# M368 register map
File version: 0.1
CPU: 
Registers are 32-bit, read-write, reset 0x0 unless marked. A register's access mark holds for its fields unless they carry their own. Offsets are from the block's base; [hi:lo] are bit positions; {n}, {i} and the like mark numbered series.

## PB — General Purpose Input_Output Port (PB)
Base 0x400C0100
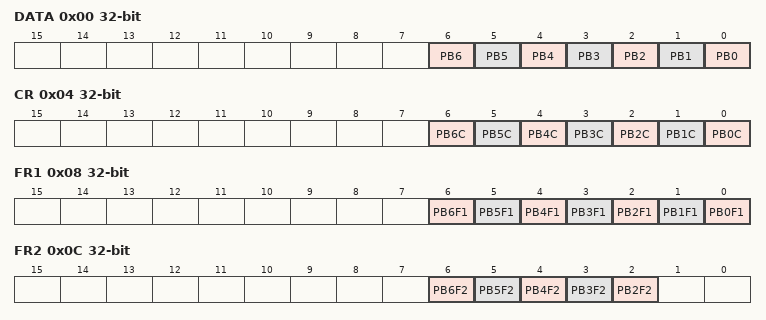
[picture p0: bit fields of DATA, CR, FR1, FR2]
0x00 DATA — PB Data Register
  [n] PB{n} (n=0..6)
0x04 CR — PB Control Register
  [n] PB{n}C (n=0..6)
0x08 FR1 — PB Function Register 1
  [n] PB{n}F1 (n=0..6)
0x0C FR2 — PB Function Register 2
  [n] PB{n}F2 (n=2..6)
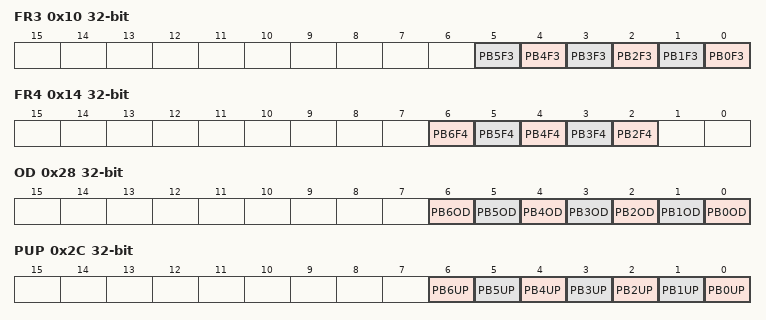
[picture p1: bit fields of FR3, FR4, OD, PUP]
0x10 FR3 — PB Function Register 3
  [n] PB{n}F3 (n=0..5)
0x14 FR4 — PB Function Register 4
  [n] PB{n}F4 (n=2..6)
0x28 OD — PB Open Drain Control Register
  [n] PB{n}OD (n=0..6)
0x2C PUP — PB Pull-Up Control Register
  [n] PB{n}UP (n=0..6)
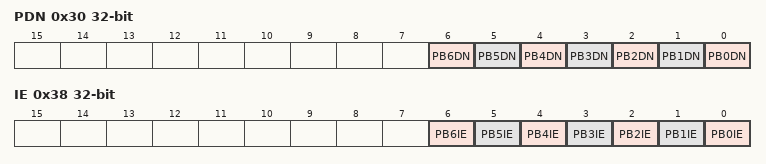
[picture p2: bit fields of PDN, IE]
0x30 PDN — PB Pull-Down Control Register
  [n] PB{n}DN (n=0..6)
0x38 IE — PB Input Enable Control Register
  [n] PB{n}IE (n=0..6)

## PE — General Purpose Input_Output Port (PE)
Base 0x400C0400
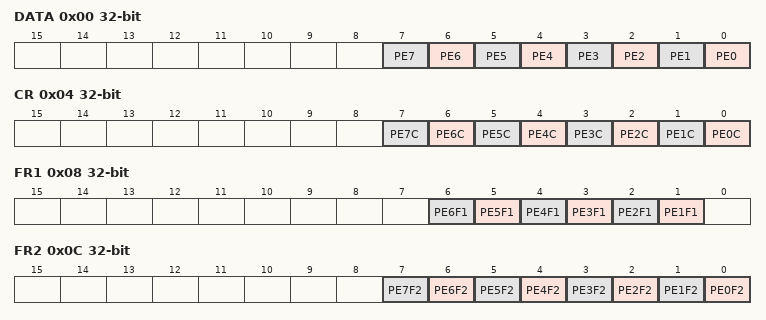
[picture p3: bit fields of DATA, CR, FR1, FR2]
0x00 DATA — PE Data Register
  [n] PE{n} (n=0..7)
0x04 CR — PE Control Register
  [n] PE{n}C (n=0..7)
0x08 FR1 — PE Function Register 1
  [n] PE{n}F1 (n=1..6)
0x0C FR2 — PE Function Register 2
  [n] PE{n}F2 (n=0..7)
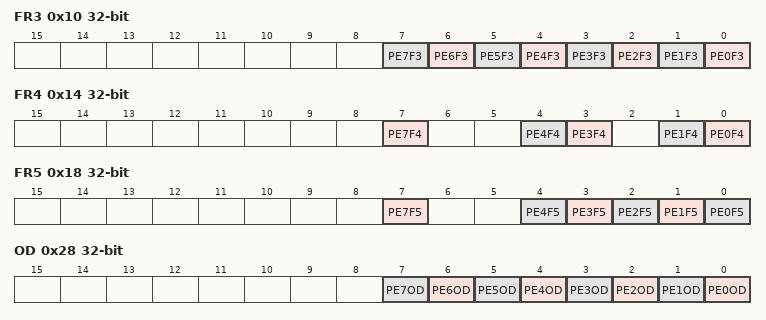
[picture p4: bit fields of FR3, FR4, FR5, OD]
0x10 FR3 — PE Function Register 3
  [n] PE{n}F3 (n=0..7)
0x14 FR4 — PE Function Register 4
  [7] PE7F4, [4] PE4F4, [3] PE3F4, [1] PE1F4, [0] PE0F4
0x18 FR5 — PE Function Register 5
  [7] PE7F5, [n] PE{n}F5 (n=0..4)
0x28 OD — PE Open Drain Control Register
  [n] PE{n}OD (n=0..7)
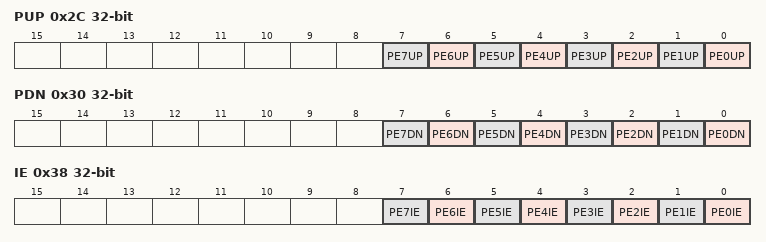
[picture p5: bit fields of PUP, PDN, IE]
0x2C PUP — PE Pull-Up Control Register
  [n] PE{n}UP (n=0..7)
0x30 PDN — PE Pull-Down Control Register
  [n] PE{n}DN (n=0..7)
0x38 IE — PE Input Enable Control Register
  [n] PE{n}IE (n=0..7)

## PF — General Purpose Input_Output Port (PF)
Base 0x400C0500
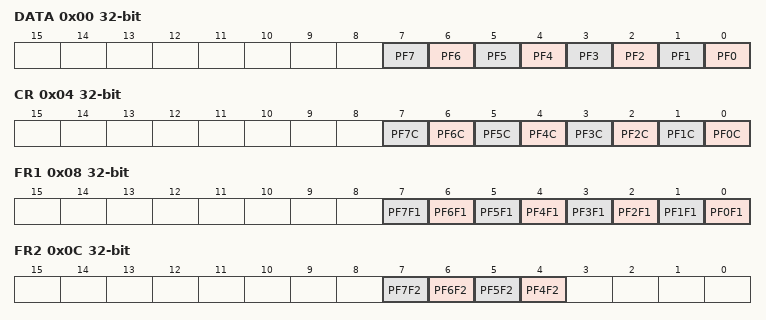
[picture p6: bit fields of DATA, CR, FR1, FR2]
0x00 DATA — PF Data Register
  [n] PF{n} (n=0..7)
0x04 CR — PF Control Register
  [n] PF{n}C (n=0..7)
0x08 FR1 — PF Function Register 1
  [n] PF{n}F1 (n=0..7)
0x0C FR2 — PF Function Register 2
  [n] PF{n}F2 (n=4..7)
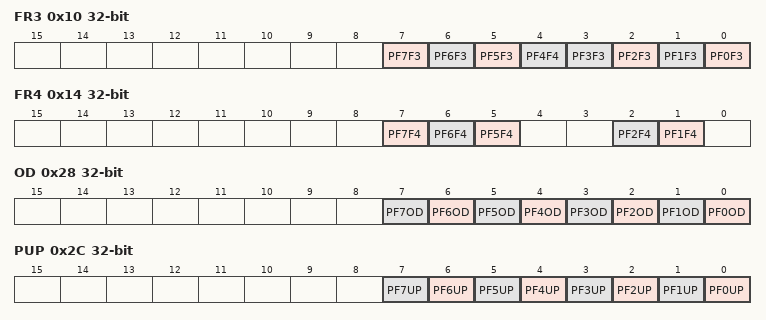
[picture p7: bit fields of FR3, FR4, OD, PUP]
0x10 FR3 — PF Function Register 3
  [7] PF7F3, [6] PF6F3, [5] PF5F3, [4] PF4F4, [n] PF{n}F3 (n=0..3)
0x14 FR4 — PF Function Register 4
  [7] PF7F4, [6] PF6F4, [5] PF5F4, [2] PF2F4, [1] PF1F4
0x28 OD — PF Open Drain Control Register
  [n] PF{n}OD (n=0..7)
0x2C PUP — PF Pull-Up Control Register
  [n] PF{n}UP (n=0..7)
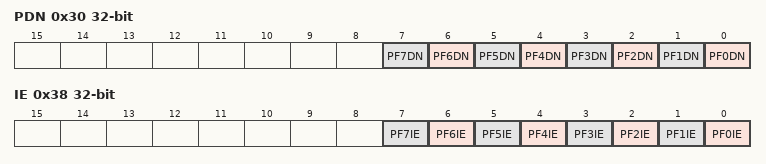
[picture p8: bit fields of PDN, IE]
0x30 PDN — PF Pull-Down Control Register
  [n] PF{n}DN (n=0..7)
0x38 IE — PF Input Enable Control Register
  [n] PF{n}IE (n=0..7)

## PG — General Purpose Input_Output Port (PG)
Base 0x400C0600
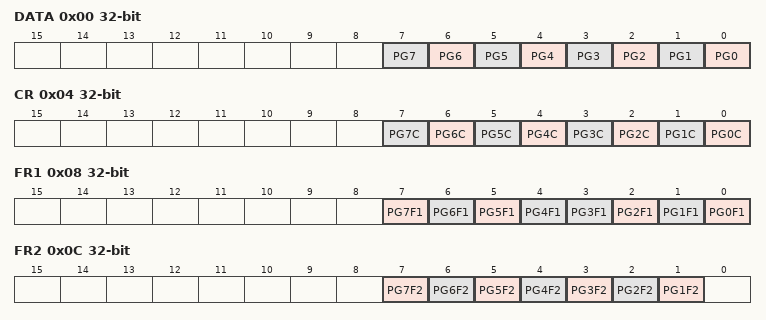
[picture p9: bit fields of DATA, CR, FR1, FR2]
0x00 DATA — PG Data Register
  [n] PG{n} (n=0..7)
0x04 CR — PG Control Register
  [n] PG{n}C (n=0..7)
0x08 FR1 — PG Function Register 1
  [7] PG7F1 ro, [6] PG6F1 ro, [5] PG5F1, [4] PG4F1 ro, [n] PG{n}F1 (n=0..3)
0x0C FR2 — PG Function Register 2
  [n] PG{n}F2 (n=1..7)
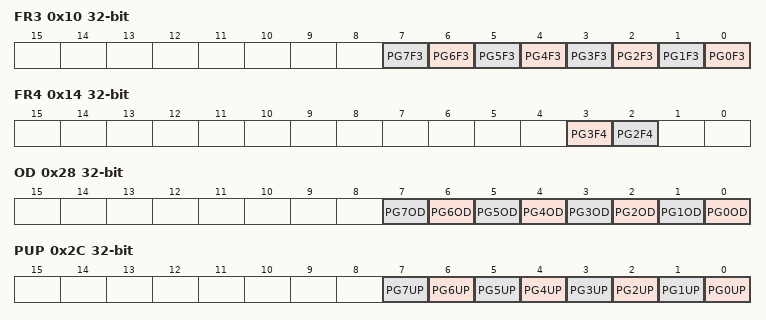
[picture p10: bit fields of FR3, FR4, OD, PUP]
0x10 FR3 — PG Function Register 3
  [n] PG{n}F3 (n=0..7)
0x14 FR4 — PG Function Register 4
  [3] PG3F4, [2] PG2F4
0x28 OD — PG Open Drain Control Register
  [n] PG{n}OD (n=0..7)
0x2C PUP — PG Pull-Up Control Register
  [n] PG{n}UP (n=0..7)
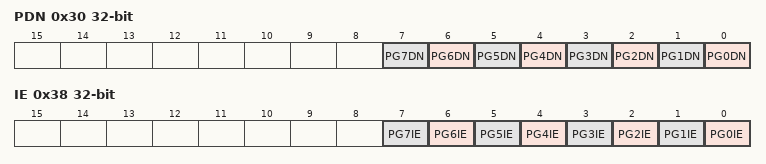
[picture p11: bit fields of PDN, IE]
0x30 PDN — PG Pull-Down Control Register
  [n] PG{n}DN (n=0..7)
0x38 IE — PG Input Enable Control Register
  [n] PG{n}IE (n=0..7)

## PH — General Purpose Input_Output Port (PH)
Base 0x400C0700
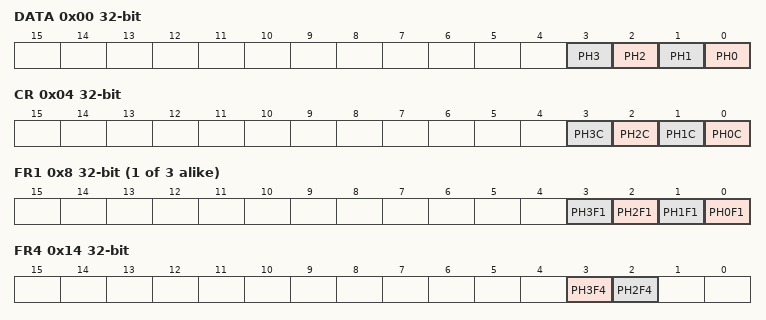
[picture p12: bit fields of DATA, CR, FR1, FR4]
0x00 DATA — PH Data Register
  [n] PH{n} (n=0..3)
0x04 CR — PH Control Register
  [n] PH{n}C (n=0..3)
{0x4+4i} FR{i} (i=1..3) — PH Function Register {i}
  [n] PH{n}F{i} (n=0..3)
0x14 FR4 — PH Function Register 4
  [3] PH3F4, [2] PH2F4
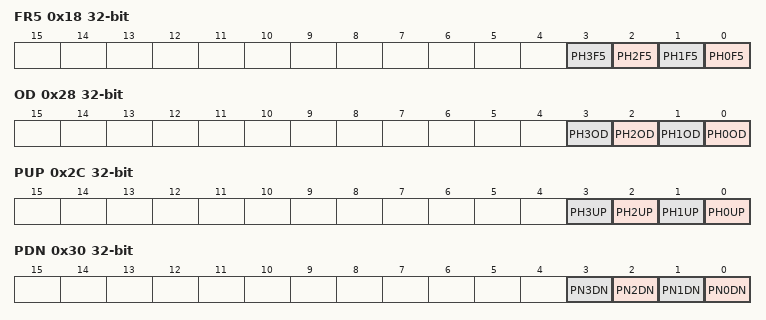
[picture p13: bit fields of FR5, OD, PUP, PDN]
0x18 FR5 — PH Function Register 5
  [n] PH{n}F5 (n=0..3)
0x28 OD — PH Open Drain Control Register
  [n] PH{n}OD (n=0..3)
0x2C PUP — PH Pull-Up Control Register
  [n] PH{n}UP (n=0..3)
0x30 PDN — PH Pull-Down Control Register
  [n] PN{n}DN (n=0..3)
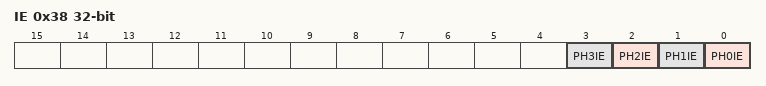
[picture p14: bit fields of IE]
0x38 IE — PH Input Enable Control Register
  [n] PH{n}IE (n=0..3)

## PI — General Purpose Input_Output Port (PI)
Base 0x400C0800
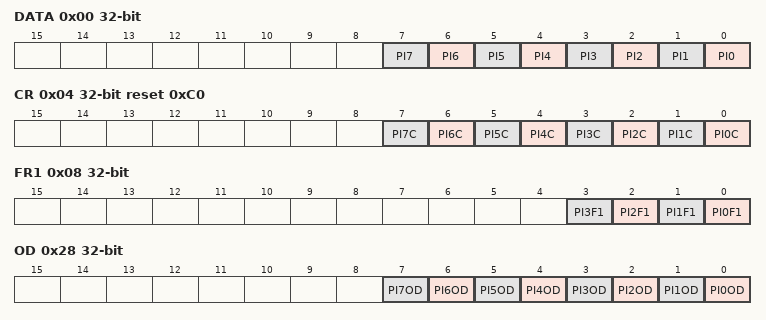
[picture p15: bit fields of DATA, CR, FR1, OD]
0x00 DATA — PI Data Register
  [n] PI{n} (n=0..7)
0x04 CR reset 0xC0 — PI Control Register
  [n] PI{n}C (n=0..7)
0x08 FR1 — PI Function Register 1
  [n] PI{n}F1 (n=0..3)
0x0C FR2 — PI Function Register 2
  [3] PI3F2
0x28 OD — PI Open Drain Control Register
  [n] PI{n}OD (n=0..7)
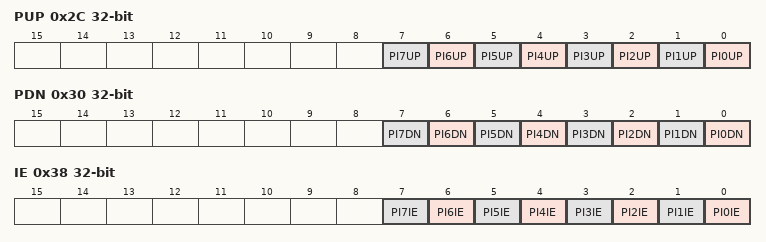
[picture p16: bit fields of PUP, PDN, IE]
0x2C PUP — PI Pull-Up Control Register
  [n] PI{n}UP (n=0..7)
0x30 PDN — PI Pull-Down Control Register
  [n] PI{n}DN (n=0..7)
0x38 IE — PI Input Enable Control Register
  [n] PI{n}IE (n=0..7)
